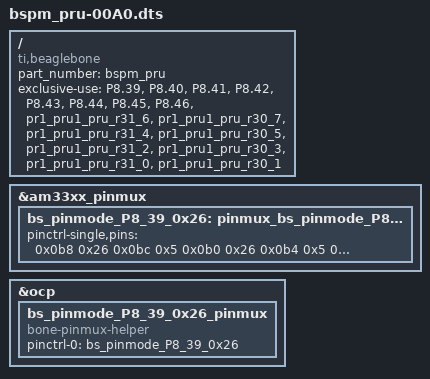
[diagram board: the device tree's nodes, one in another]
/*
 * Enables GPIO pins for direct PRU fast-mode access.
 * Based on generator at:
 * http://kilobaser.com/blog/2014-07-28-beaglebone-black-devicetreeoverlay-generator
 */
/dts-v1/;
/plugin/;

/{
    compatible = "ti,beaglebone", "ti,beaglebone-black";
    part_number = "bspm_pru";

    exclusive-use =
        "P8.39",
	    "P8.40",
	    "P8.41",
	    "P8.42",
	    "P8.43",
	    "P8.44",
	    "P8.45",
	    "P8.46",
        "pr1_pru1_pru_r31_6",
        "pr1_pru1_pru_r30_7",
        "pr1_pru1_pru_r31_4",
        "pr1_pru1_pru_r30_5",
        "pr1_pru1_pru_r31_2",
        "pr1_pru1_pru_r30_3",
        "pr1_pru1_pru_r31_0",
        "pr1_pru1_pru_r30_1";

    fragment@0 {
        target = <&am33xx_pinmux>;
        __overlay__ {
            bs_pinmode_P8_39_0x26: pinmux_bs_pinmode_P8_39_0x26 {
                pinctrl-single,pins = <0x0b8 0x26 0x0bc 0x5 0x0b0 0x26 0x0b4 0x5 0x0a8 0x26 0x0ac 0x5 0x0a0 0x26 0x0a4 0x5>;
            };
        };
    };

    fragment@1 {
        target = <&ocp>;
        __overlay__ {
            bs_pinmode_P8_39_0x26_pinmux {
                compatible = "bone-pinmux-helper";
                status = "okay";
                pinctrl-names = "default";
                pinctrl-0 = <&bs_pinmode_P8_39_0x26>;
            };
        };
    };
};
